# PY32F040xx register map
Vendor: Puya; Series: PY32F0; File version: 1.0.0
CPU: CM0+ r0p1, little endian, no MPU, no FPU, 4 interrupt priority bits
Registers are 32-bit, read-write, reset 0x0 unless marked. A register's access mark holds for its fields unless they carry their own. Offsets are from the block's base; [hi:lo] are bit positions; {n}, {i} and the like mark numbered series; 'fields as' and 'values as' point back to an identical list.

## SYSCFG
Base 0x40010000
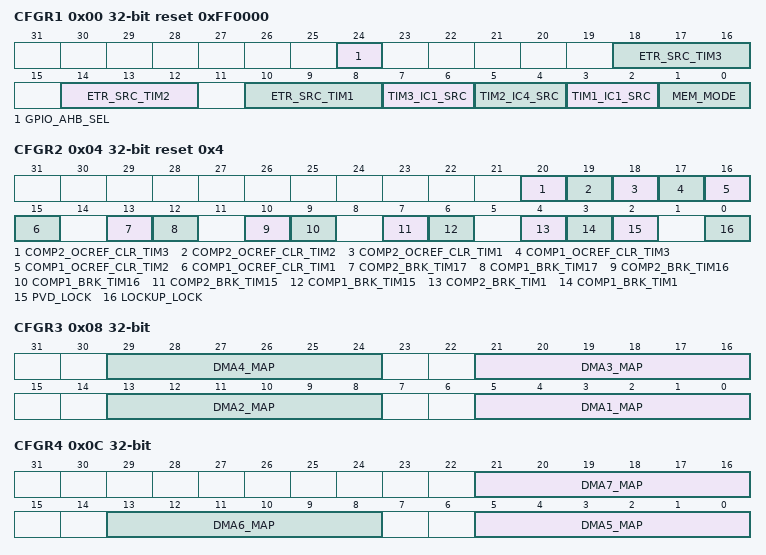
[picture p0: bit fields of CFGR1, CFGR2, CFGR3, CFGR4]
0x00 CFGR1 reset 0xFF0000
  [24] GPIO_AHB_SEL
    0=Fast IO bus access to GPIO register control; 1=AHB (AHB bus access to GPIO register control)
  [18:16] ETR_SRC_TIM3
    0=GPIO (TIM*_ETR is connected to GPIO); 1=COMP1 (TIM*_ETR is connected to COMP1); 2=COMP2 (TIM*_ETR is connected to COMP2); 3=ADC (TIM*_ETR is connected to ADC)
  [14:12] ETR_SRC_TIM2
    values as ETR_SRC_TIM3
  [10:8] ETR_SRC_TIM1
    values as ETR_SRC_TIM3
  [7:6] TIM3_IC1_SRC
    0=Standard (From TIM?_CH* IO); 1=Comp1 (From Comp 1); 2=Comp2 (From Comp 2); 3=Comp3 (From Comp 3)
  [5:4] TIM2_IC4_SRC
    values as TIM3_IC1_SRC
  [3:2] TIM1_IC1_SRC
    values as TIM3_IC1_SRC
  [1:0] MEM_MODE
    0=Main Flash memory mapped at 0x0000_0000; 1=System Flash memory mapped at 0x0000_0000; 2=MainFlash2 (Main Flash memory mapped at 0x0000_0000); 3=SRAM (Embedded SRAM mapped at 0x0000_0000)
0x04 CFGR2 reset 0x4
  [20] COMP2_OCREF_CLR_TIM3
    0=NotUsed (COMP? output not used as TIM? ocref_clr input); 1=Used (COMP? output used as TIM? ocref_clr input)
  [19] COMP2_OCREF_CLR_TIM2
    values as COMP2_OCREF_CLR_TIM3
  [18] COMP2_OCREF_CLR_TIM1
    values as COMP2_OCREF_CLR_TIM3
  [17] COMP1_OCREF_CLR_TIM3
    values as COMP2_OCREF_CLR_TIM3
  [16] COMP1_OCREF_CLR_TIM2
    values as COMP2_OCREF_CLR_TIM3
  [15] COMP1_OCREF_CLR_TIM1
    values as COMP2_OCREF_CLR_TIM3
  [13] COMP2_BRK_TIM17
    0=Disconnected (COMP? output not connect to TIM? Break input); 1=Connected (COMP? output connected to TIM? Break input)
  [12] COMP1_BRK_TIM17
    values as COMP2_BRK_TIM17
  [10] COMP2_BRK_TIM16
    values as COMP2_BRK_TIM17
  [9] COMP1_BRK_TIM16
    values as COMP2_BRK_TIM17
  [7] COMP2_BRK_TIM15
    values as COMP2_BRK_TIM17
  [6] COMP1_BRK_TIM15
    values as COMP2_BRK_TIM17
  [4] COMP2_BRK_TIM1
    values as COMP2_BRK_TIM17
  [3] COMP1_BRK_TIM1
    values as COMP2_BRK_TIM17
  [2] PVD_LOCK
    0=Disconnected (PVD LOCKUP output disconnected from TIM1/16/17 Break input); 1=Connected (PVD LOCKUP output connected to TIM1/16/17 Break input)
  [0] LOCKUP_LOCK
    0=Disconnected (Cortex-M0+ LOCKUP output disconnected from TIM1/16/17 Break input); 1=Connected (Cortex-M0+ LOCKUP output connected to TIM1/16/17 Break input)
0x08 CFGR3
  [all] fields
    0=ADC (ADC DMA requests mapped on DMA?); 3=SPI1_TX (SPI1_TX DMA requests mapped on DMA?); 4=SPI1_RX (SPI1_RX DMA requests mapped on DMA?); 5=SPI2_TX (SPI2_TX DMA requests mapped on DMA?); 6=SPI2_RX (SPI2_RX DMA requests mapped on DMA?); 7=USART1_TX (USART1_TX DMA requests mapped on DMA?); 8=USART1_RX (USART1_RX DMA requests mapped on DMA?); 9=USART2_TX (USART2_TX DMA requests mapped on DMA?); 10=USART2_RX (USART2_RX DMA requests mapped on DMA?); 11=USART3_TX (USART3_TX DMA requests mapped on DMA?); 12=USART3_RX (USART3_RX DMA requests mapped on DMA?); 13=USART4_TX (USART4_TX DMA requests mapped on DMA?); 14=USART4_RX (USART4_RX DMA requests mapped on DMA?); 15=I2C1_TX (I2C1_TX DMA requests mapped on DMA?); 16=I2C1_RX (I2C1_RX DMA requests mapped on DMA?); 17=I2C2_TX (I2C2_TX DMA requests mapped on DMA?); 18=I2C2_RX (I2C2_RX DMA requests mapped on DMA?); {v}=TIM1_CH{v-18} (TIM1_CH{v-18} DMA requests mapped on DMA?) (v=19..22); 23=TIM1_COM (TIM1_COM DMA requests mapped on DMA?); 24=TIM1_TRIG (TIM1_TRIG DMA requests mapped on DMA?); 25=TIM1_UP (TIM1_UP DMA requests mapped on DMA?); {v}=TIM2_CH{v-25} (TIM2_CH{v-25} DMA requests mapped on DMA?) (v=26..29); 30=TIM2_UP (TIM2_UP DMA requests mapped on DMA?); 31=TIM2_TRIG (TIM2_TRIG DMA requests mapped on DMA?); {v}=TIM3_CH{v-31} (TIM3_CH{v-31} DMA requests mapped on DMA?) (v=32..35); 36=TIM3_UP (TIM3_UP DMA requests mapped on DMA?); 37=TIM3_TRIG (TIM3_TRIG DMA requests mapped on DMA?); 38=TIM6_UP (TIM6_UP DMA requests mapped on DMA?); 39=TIM7_UP (TIM7_UP DMA requests mapped on DMA?); 40=TIM15_CH1 (TIM15_CH1 DMA requests mapped on DMA?); 41=TIM15_CH2 (TIM15_CH2 DMA requests mapped on DMA?); 42=TIM15_UP (TIM15_UP DMA requests mapped on DMA?); 43=TIM15_TRIG (TIM15_TRIG DMA requests mapped on DMA?); 44=TIM15_COM (TIM15_COM DMA requests mapped on DMA?); 45=TIM16_CH1 (TIM16_CH1 DMA requests mapped on DMA?); 46=TIM16_UP (TIM16_UP DMA requests mapped on DMA?); 47=TIM17_CH1 (TIM17_CH1 DMA requests mapped on DMA?); 48=TIM17_UP (TIM17_UP DMA requests mapped on DMA?); 49=LCD (LCD DMA requests mapped on DMA?)
  [8n-3:8n-8] DMA{n}_MAP (n=1..4)
0x0C CFGR4
  [all] fields
    values as the fields of CFGR3
  [21:16] DMA7_MAP
  [13:8] DMA6_MAP
  [5:0] DMA5_MAP
0x10 PAENS
  [15:0] PA_ENS
0x14 PBENS
  [15:0] PB_ENS
0x18 PCENS
  [15:0] PC_ENS
0x1C PFENS
  [15:0] PF_ENS
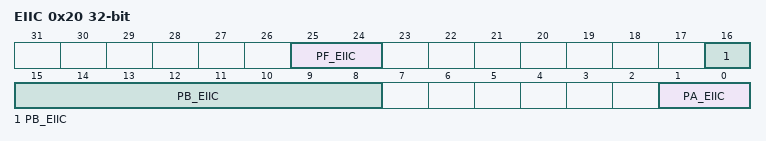
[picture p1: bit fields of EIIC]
0x20 EIIC
  [25:24] PF_EIIC, [16:8] PB_EIIC, [1:0] PA_EIIC
